AUTOSAR XML (schema 4-2-2)
package /System
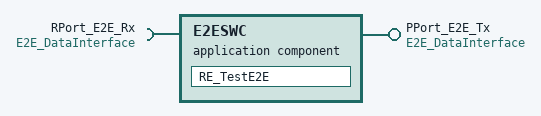
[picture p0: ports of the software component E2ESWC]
  application sw component type E2ESWC
    require port RPort_E2E_Rx: required-interface=E2E_DataInterface
    provide port PPort_E2E_Tx: provided-interface=E2E_DataInterface
    behavior InternalBehavior
      data received event DRE_TestE2E: start-on-event=RE_TestE2E, data=RPort_E2E_Rx.Data
      runnable RE_TestE2E
        data-receive-point-by-arguments:
          access DRAE2E_Cks: accessed-variable=RPort_E2E_Rx.CKS
          access DRAE2E_Data: accessed-variable=RPort_E2E_Rx.Data
          access DRAE2E_Alive_Cnt: accessed-variable=RPort_E2E_Rx.Alive_Cnt
        data-send-points:
          access DWAE2E_Cks: accessed-variable=PPort_E2E_Tx.CKS
          access DWAE2E_Data: accessed-variable=PPort_E2E_Tx.Data
          access DWAE2E_Alive_Cnt: accessed-variable=PPort_E2E_Tx.Alive_Cnt
